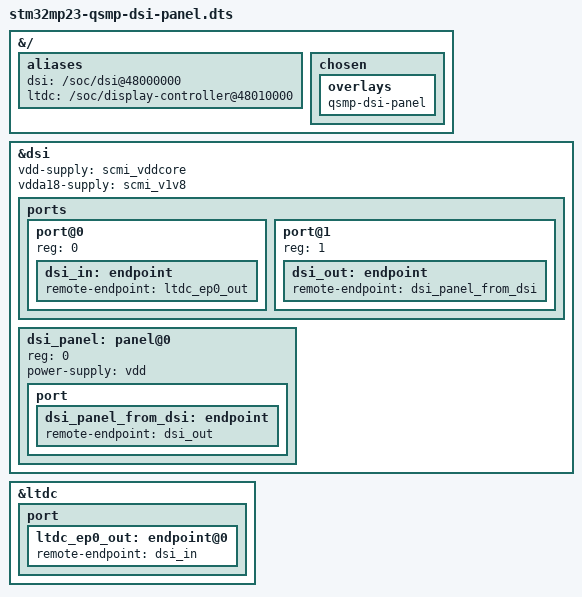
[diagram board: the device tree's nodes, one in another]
// SPDX-License-Identifier: (GPL-2.0-only OR BSD-3-Clause)
/*
 * Copyright (C) 2025 Marcel Mertens <MM@KARO-electronics.de>
 *
 */

/dts-v1/;

/plugin/;

&{/} {
	aliases {
		dsi = "/soc/dsi@48000000";
		ltdc = "/soc/display-controller@48010000";
	};

	chosen {
		overlays {
			qsmp-dsi-panel;
		};
	};
};

&dsi {
	vdd-supply =  <&scmi_vddcore>;
	vdda18-supply = <&scmi_v1v8>;
	status = "okay";

	ports {
		#address-cells = <1>;
		#size-cells = <0>;

		port@0 {
			reg = <0>;
			dsi_in: endpoint {
				remote-endpoint = <&ltdc_ep0_out>;
			};
		};

		port@1 {
			reg = <1>;
			dsi_out: endpoint {
				remote-endpoint = <&dsi_panel_from_dsi>;
			};
		};
	};

	dsi_panel: panel@0 {
		reg = <0>;
		power-supply = <&vdd>;
		status = "okay";

		port {
			dsi_panel_from_dsi: endpoint {
				remote-endpoint = <&dsi_out>;
			};
		};
	};
};

&ltdc {
	status = "okay";

	port {
		#address-cells = <1>;
		#size-cells = <0>;

		ltdc_ep0_out: endpoint@0 {
			remote-endpoint = <&dsi_in>;
		};
	};
};
